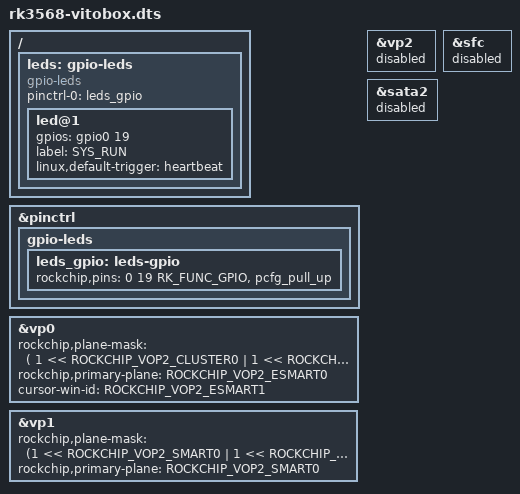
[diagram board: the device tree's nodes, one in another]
// SPDX-License-Identifier: (GPL-2.0+ OR MIT)
/*
 * Copyright (c) 2020 Rockchip Electronics Co., Ltd.
 *
 */

#include "rk3568-evb1-ddr4-v10.dtsi"
#include "rk3568-linux.dtsi"
#include <dt-bindings/display/rockchip_vop.h>


/ {
	leds: gpio-leds {
		compatible = "gpio-leds";
		pinctrl-names = "default";
		pinctrl-0 =<&leds_gpio>;

		led@1 {
			gpios = <&gpio0 19 GPIO_ACTIVE_HIGH>;
			label = "SYS_RUN";
			linux,default-trigger = "heartbeat";				
		};
	};
};

&pinctrl {
	gpio-leds {
			leds_gpio: leds-gpio {
					rockchip,pins = <0 19 RK_FUNC_GPIO &pcfg_pull_up>;
		};
	};
};

&vp0 {
	rockchip,plane-mask = <(
				1 << ROCKCHIP_VOP2_CLUSTER0 | 1 << ROCKCHIP_VOP2_ESMART0 |
				1 << ROCKCHIP_VOP2_CLUSTER1 | 1 << ROCKCHIP_VOP2_ESMART1 )>;
	rockchip,primary-plane = <ROCKCHIP_VOP2_ESMART0>;
	cursor-win-id = <ROCKCHIP_VOP2_ESMART1>;
};

&vp1 {
	rockchip,plane-mask = <(1 << ROCKCHIP_VOP2_SMART0 | 1 << ROCKCHIP_VOP2_SMART1)>;
	rockchip,primary-plane = <ROCKCHIP_VOP2_SMART0>;
};

&vp2 {
	status = "disabled";
};


&sfc {
	status = "disabled";
};

&sata2 {
	status = "disabled";
};
